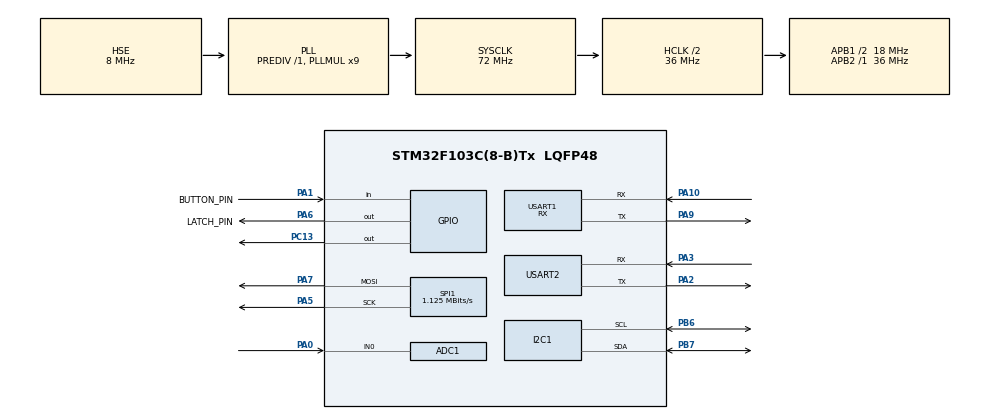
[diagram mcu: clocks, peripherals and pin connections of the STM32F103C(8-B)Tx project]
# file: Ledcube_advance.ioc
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ADC1.Channel-2\#ChannelRegularConversion=ADC_CHANNEL_0
ADC1.NbrOfConversionFlag=1
ADC1.Rank-2\#ChannelRegularConversion=1
ADC1.SamplingTime-2\#ChannelRegularConversion=ADC_SAMPLETIME_1CYCLE_5
ADC1.master=1
Mcu.Family=STM32F1
Mcu.Name=STM32F103C(8-B)Tx
Mcu.Package=LQFP48
NVIC.PriorityGroup=NVIC_PRIORITYGROUP_4
NVIC.TIM2_IRQn=true\:2\:0\:true\:false\:true\:true\:true\:true
NVIC.USART1_IRQn=true\:0\:0\:false\:false\:true\:true\:true\:true
NVIC.USART2_IRQn=true\:0\:0\:false\:false\:true\:true\:true\:true
PA0-WKUP.Signal=ADCx_IN0
PA1.GPIO_Label=BUTTON_PIN
PA1.GPIO_PuPd=GPIO_PULLUP
PA1.Signal=GPIO_Input
PA10.Mode=Asynchronous
PA10.Signal=USART1_RX
PA13.Mode=Serial_Wire
PA13.Signal=SYS_JTMS-SWDIO
PA14.Mode=Serial_Wire
PA14.Signal=SYS_JTCK-SWCLK
PA2.Mode=Asynchronous
PA2.Signal=USART2_TX
PA3.Mode=Asynchronous
PA3.Signal=USART2_RX
PA5.Mode=TX_Only_Simplex_Unidirect_Master
PA5.Signal=SPI1_SCK
PA6.GPIO_Label=LATCH_PIN
PA6.Signal=GPIO_Output
PA7.Mode=TX_Only_Simplex_Unidirect_Master
PA7.Signal=SPI1_MOSI
PA9.Mode=Asynchronous
PA9.Signal=USART1_TX
PB6.Mode=I2C
PB6.Signal=I2C1_SCL
PB7.Mode=I2C
PB7.Signal=I2C1_SDA
PC13-TAMPER-RTC.Signal=GPIO_Output
PD0-OSC_IN.Mode=HSE-External-Oscillator
PD0-OSC_IN.Signal=RCC_OSC_IN
PD1-OSC_OUT.Mode=HSE-External-Oscillator
PD1-OSC_OUT.Signal=RCC_OSC_OUT
ProjectManager.HeapSize=0x200
ProjectManager.StackSize=0x400
ProjectManager.TargetToolchain=STM32CubeIDE
RCC.ADCPresc=RCC_ADCPCLK2_DIV4
RCC.AHBCLKDivider=RCC_SYSCLK_DIV2
RCC.AHBFreq_Value=36000000
RCC.APB1CLKDivider=RCC_HCLK_DIV2
RCC.APB1Freq_Value=18000000
RCC.APB1TimFreq_Value=36000000
RCC.APB2Freq_Value=36000000
RCC.APB2TimFreq_Value=36000000
RCC.HCLKFreq_Value=36000000
RCC.PLLMUL=RCC_PLL_MUL9
RCC.PLLSourceVirtual=RCC_PLLSOURCE_HSE
RCC.SYSCLKFreq_VALUE=72000000
RCC.SYSCLKSource=RCC_SYSCLKSOURCE_PLLCLK
RCC.USBFreq_Value=72000000
SH.ADCx_IN0.0=ADC1_IN0,IN0
SPI1.BaudRatePrescaler=SPI_BAUDRATEPRESCALER_32
SPI1.CalculateBaudRate=1.125 MBits/s
SPI1.Direction=SPI_DIRECTION_2LINES
SPI1.Mode=SPI_MODE_MASTER
SPI1.VirtualType=VM_MASTER
TIM2.AutoReloadPreload=TIM_AUTORELOAD_PRELOAD_ENABLE
TIM2.Period=1000-1
TIM2.Prescaler=\ 36-1
USART1.Mode=MODE_RX
USART1.VirtualMode=VM_ASYNC
USART2.VirtualMode=VM_ASYNC
VP_TIM2_VS_ClockSourceINT.Mode=Internal
board=custom

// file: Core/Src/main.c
/* USER CODE BEGIN Header */
/**
  ******************************************************************************
  * @file           : main.c
  * @brief          : Main program body
  ******************************************************************************
  * @attention
  *
  * Copyright (c) 2022 STMicroelectronics.
  * All rights reserved.
  *
  * This software is licensed under terms that can be found in the LICENSE file
  * in the root directory of this software component.
  * If no LICENSE file comes with this software, it is provided AS-IS.
  *
  ******************************************************************************
  */
/* USER CODE END Header */
#include "main.h"
#include "adc.h"
#include "i2c.h"
#include "spi.h"
#include "tim.h"
#include "usart.h"
#include "gpio.h"

/* USER CODE BEGIN Includes */
#include "led_cube_handle.h"
/* USER CODE END Includes */

/* USER CODE BEGIN PV */
Btn_Typedef button1;
/* USER CODE END PV */

void SystemClock_Config(void);

int main(void)
{

  /* MCU Configuration--------------------------------------------------------*/

  /* Reset of all peripherals, Initializes the Flash interface and the Systick. */
  HAL_Init();

  /* Configure the system clock */
  SystemClock_Config();

  /* Initialize all configured peripherals */
  MX_GPIO_Init();
  MX_SPI1_Init();
  MX_USART1_UART_Init();
  MX_USART2_UART_Init();
  MX_ADC1_Init();
  MX_TIM2_Init();
  MX_I2C1_Init();
  /* USER CODE BEGIN 2 */
  Btn_Init(&button1, GPIOA, GPIO_PIN_1);
  //Btn_app(&button1);
  Effect_app();
  HAL_TIM_Base_Start_IT(&htim2);
  /* USER CODE END 2 */

  /* Infinite loop */
  while (1)
  {

    /* USER CODE BEGIN 3 */
	  //Btn_Handle(&button1);
	  //Led_cube_Handle(currentEffect);
  }
  /* USER CODE END 3 */
}

void SystemClock_Config(void)
{
  RCC_OscInitTypeDef RCC_OscInitStruct = {0};
  RCC_ClkInitTypeDef RCC_ClkInitStruct = {0};
  RCC_PeriphCLKInitTypeDef PeriphClkInit = {0};

  /** Initializes the RCC Oscillators according to the specified parameters
  * in the RCC_OscInitTypeDef structure.
  */
  RCC_OscInitStruct.OscillatorType = RCC_OSCILLATORTYPE_HSE;
  RCC_OscInitStruct.HSEState = RCC_HSE_ON;
  RCC_OscInitStruct.HSEPredivValue = RCC_HSE_PREDIV_DIV1;
  RCC_OscInitStruct.HSIState = RCC_HSI_ON;
  RCC_OscInitStruct.PLL.PLLState = RCC_PLL_ON;
  RCC_OscInitStruct.PLL.PLLSource = RCC_PLLSOURCE_HSE;
  RCC_OscInitStruct.PLL.PLLMUL = RCC_PLL_MUL9;
  if (HAL_RCC_OscConfig(&RCC_OscInitStruct) != HAL_OK)
  {
    Error_Handler();
  }

  /** Initializes the CPU, AHB and APB buses clocks
  */
  RCC_ClkInitStruct.ClockType = RCC_CLOCKTYPE_HCLK|RCC_CLOCKTYPE_SYSCLK
                              |RCC_CLOCKTYPE_PCLK1|RCC_CLOCKTYPE_PCLK2;
  RCC_ClkInitStruct.SYSCLKSource = RCC_SYSCLKSOURCE_PLLCLK;
  RCC_ClkInitStruct.AHBCLKDivider = RCC_SYSCLK_DIV2;
  RCC_ClkInitStruct.APB1CLKDivider = RCC_HCLK_DIV2;
  RCC_ClkInitStruct.APB2CLKDivider = RCC_HCLK_DIV1;

  if (HAL_RCC_ClockConfig(&RCC_ClkInitStruct, FLASH_LATENCY_2) != HAL_OK)
  {
    Error_Handler();
  }
  PeriphClkInit.PeriphClockSelection = RCC_PERIPHCLK_ADC;
  PeriphClkInit.AdcClockSelection = RCC_ADCPCLK2_DIV4;
  if (HAL_RCCEx_PeriphCLKConfig(&PeriphClkInit) != HAL_OK)
  {
    Error_Handler();
  }
}

void Error_Handler(void)
{
  __disable_irq();
  while (1)
  {
  }
}
